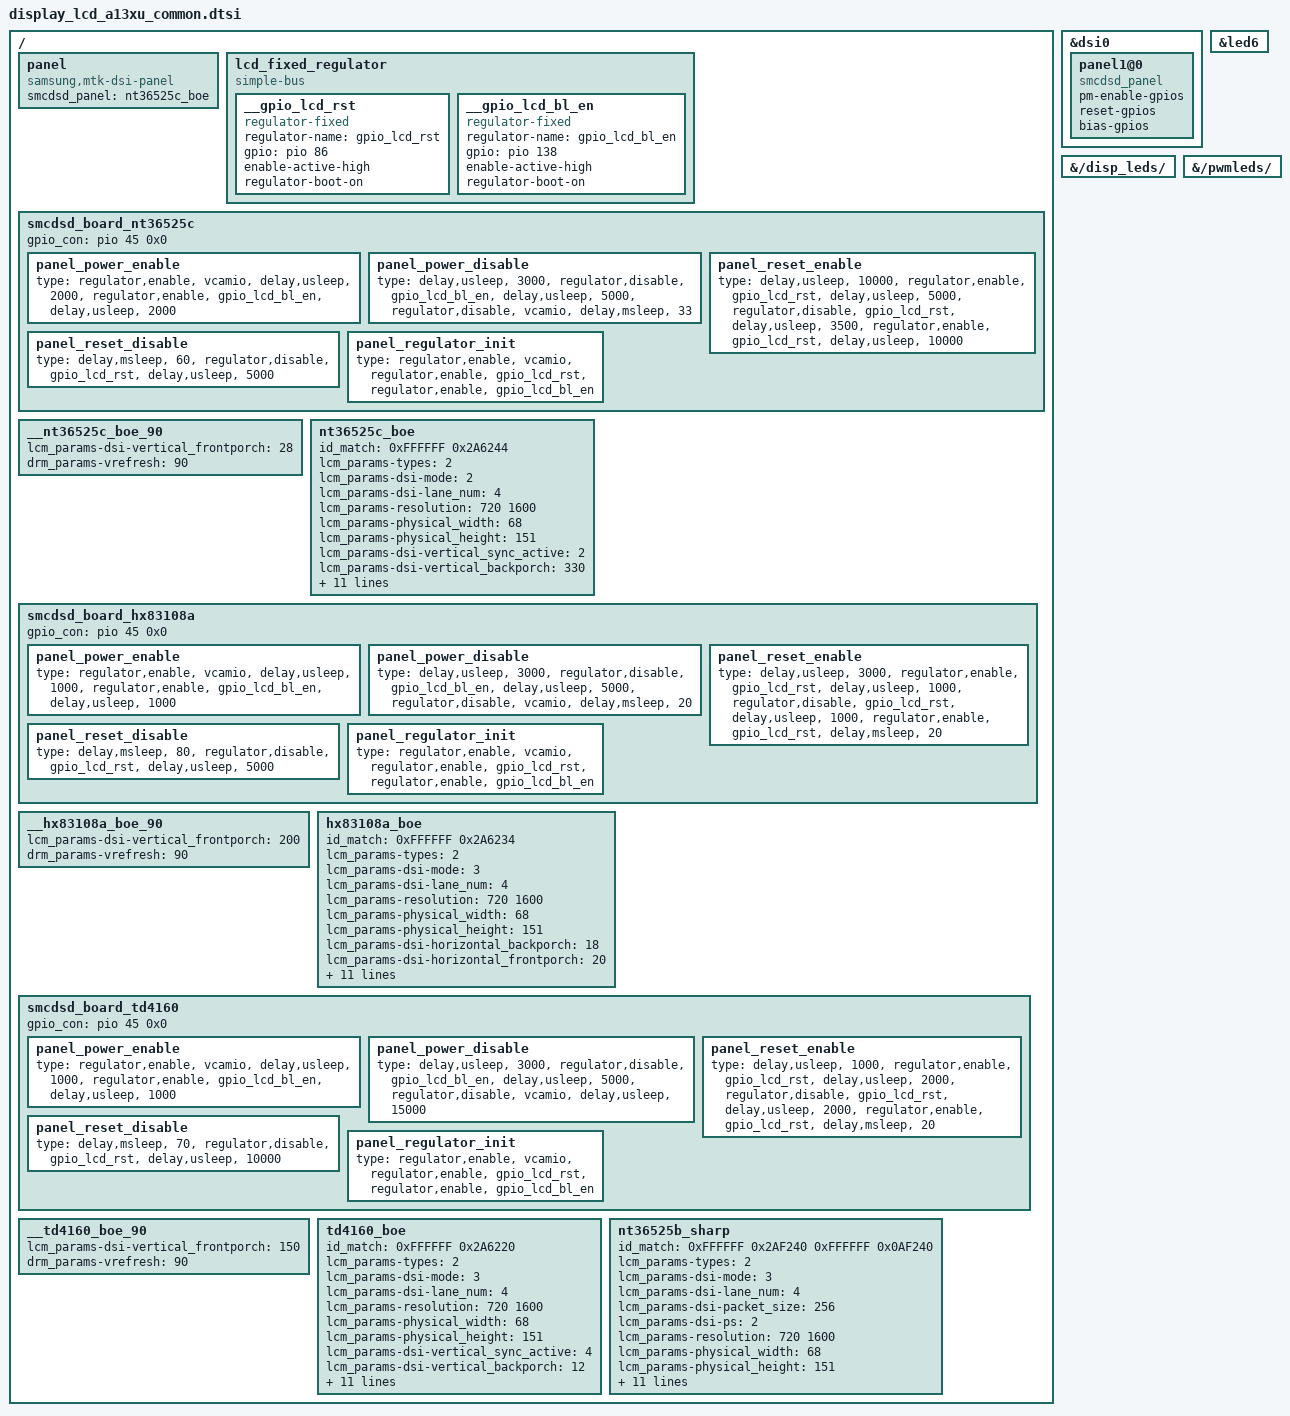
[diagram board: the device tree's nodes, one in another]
/*
 * SAMSUNG LCD Panel Device Tree Source
 *
 * Copyright (c) Samsung Electronics Co., Ltd.
 *		http://www.samsung.com
 *
 * This program is free software; you can redistribute it and/or modify
 * it under the terms of the GNU General Public License version 2 as
 * published by the Free Software Foundation.
 */

/ {
	fragment@led {
		target-path = "/disp_leds/";
		__overlay__ {
			compatible;
		};
	};

	fragment@pwm {
		target-path = "/pwmleds/";
		__overlay__ {
			compatible;
		};
	};

	fragment@lcd {
		target-path = "/";
		__overlay__ {
			panel {
				compatible = "samsung,mtk-dsi-panel";
				smcdsd_panel = <&nt36525c_boe>;
			};

			lcd_fixed_regulator: lcd_fixed_regulator {
				compatible = "simple-bus";

				__gpio_lcd_rst: __gpio_lcd_rst {
					compatible = "regulator-fixed";
					regulator-name = "gpio_lcd_rst";
					gpio = <&pio 86 0>;	/* LCD_RST */
					enable-active-high;
					regulator-boot-on;
				};
				__gpio_lcd_bl_en: __gpio_lcd_bl_en {
					compatible = "regulator-fixed";
					regulator-name = "gpio_lcd_bl_en";
					gpio = <&pio 138 0>;	/* LCD_BL_EN */
					enable-active-high;
					regulator-boot-on;
				};
			};

			smcdsd_board_nt36525c: smcdsd_board_nt36525c {
				gpio_con = <&pio 45 0x0>;	/* LCD_CON_DET */
				//gpio_det = <&pio 6 0x1>;	/* LCD_ESD_DET */

				panel_power_enable {
					type =
					"regulator,enable",	"vcamio",
					"delay,usleep",	"2000",
					"regulator,enable",	"gpio_lcd_bl_en",
					"delay,usleep",	"2000";
				};
				panel_power_disable {
					type =
					"delay,usleep",	"3000",
					"regulator,disable",	"gpio_lcd_bl_en",
					"delay,usleep",	"5000",
					"regulator,disable",	"vcamio",
					"delay,msleep",	"33";
				};
				panel_reset_enable {
					type =
					"delay,usleep",	"10000",
					"regulator,enable",	"gpio_lcd_rst",
					"delay,usleep",	"5000",
					"regulator,disable",	"gpio_lcd_rst",
					"delay,usleep",	"3500",
					"regulator,enable",	"gpio_lcd_rst",
					"delay,usleep",	"10000";
				};
				panel_reset_disable {
					type =
					"delay,msleep",	"60",
					"regulator,disable",	"gpio_lcd_rst",
					"delay,usleep",	"5000";
				};
				panel_regulator_init {
					type =
					"regulator,enable",	"vcamio",
					"regulator,enable",	"gpio_lcd_rst",
					"regulator,enable",	"gpio_lcd_bl_en";
				};
			};

			__nt36525c_boe_90: __nt36525c_boe_90 {
				lcm_params-dsi-vertical_frontporch = <28>;	/* 60Hz: 1009, 90Hz: 28 */

				drm_params-vrefresh = <90>;
			};

			nt36525c_boe: nt36525c_boe {
				/* id_match: MASK(HEX) EXPECT(HEX) */
				id_match = <
					0xFFFFFF 0x2A6244	/* A13X */
				>;
				lcm_params-types = <2>; /* 0: LCM_TYPE_DBI, 1: LCM_TYPE_DPI, 2: LCM_TYPE_DSI */
				lcm_params-dsi-mode = <2>;	/* 0: CMD, 1: SYNC_PULSE_VDO, 2: SYNC_EVENT_VDO, 3: BURST_VDO */
				lcm_params-dsi-lane_num = <4>;

				lcm_params-resolution = <720 1600>;
				lcm_params-physical_width = <68>;		/* 67.93mm x 150.96mm */
				lcm_params-physical_height = <151>;

				lcm_params-dsi-vertical_sync_active = <2>;
				lcm_params-dsi-vertical_backporch = <330>;
				lcm_params-dsi-vertical_frontporch = <1009>;	/* 60Hz: 1009, 90Hz: 28 */
				lcm_params-dsi-horizontal_sync_active = <2>;
				lcm_params-dsi-horizontal_backporch = <34>;
				lcm_params-dsi-horizontal_frontporch = <24>;

				lcm_params-dsi-data_rate = <898>;
				lcm_params-dsi-ssc_disable = <1>;
				lcm_params-dsi-cont_clock = <1>;

				drm_params-vrefresh = <60>;

				ext_params-dyn_fps-vact_timing_fps = <90>;

				vrr_info = <&nt36525c_boe &__nt36525c_boe_90>;

				smcdsd_board = <&smcdsd_board_nt36525c>;
			};

			smcdsd_board_hx83108a: smcdsd_board_hx83108a {
				gpio_con = <&pio 45 0x0>;	/* LCD_CON_DET */
				//gpio_det = <&pio 6 0x1>;	/* LCD_ESD_DET */

				panel_power_enable {
					type =
					"regulator,enable",	"vcamio",
					"delay,usleep",	"1000",
					"regulator,enable",	"gpio_lcd_bl_en",
					"delay,usleep",	"1000";
				};
				panel_power_disable {
					type =
					"delay,usleep",	"3000",
					"regulator,disable",	"gpio_lcd_bl_en",
					"delay,usleep",	"5000",
					"regulator,disable",	"vcamio",
					"delay,msleep",	"20";
				};
				panel_reset_enable {
					type =
					"delay,usleep",	"3000",
					"regulator,enable",	"gpio_lcd_rst",
					"delay,usleep",	"1000",
					"regulator,disable",	"gpio_lcd_rst",
					"delay,usleep",	"1000",
					"regulator,enable",	"gpio_lcd_rst",
					"delay,msleep",	"20";
				};
				panel_reset_disable {
					type =
					"delay,msleep",	"80",
					"regulator,disable",	"gpio_lcd_rst",
					"delay,usleep",	"5000";
				};
				panel_regulator_init {
					type =
					"regulator,enable",	"vcamio",
					"regulator,enable",	"gpio_lcd_rst",
					"regulator,enable",	"gpio_lcd_bl_en";
				};
			};

			__hx83108a_boe_90: __hx83108a_boe_90 {
				lcm_params-dsi-vertical_frontporch = <200>;	/* 60Hz: 1116, 90Hz: 200 */

				drm_params-vrefresh = <90>;
			};

			hx83108a_boe: hx83108a_boe {
				/* id_match: MASK(HEX) EXPECT(HEX) */
				id_match = <
					0xFFFFFF 0x2A6234	/* A13X */
				>;
				lcm_params-types = <2>; /* 0: LCM_TYPE_DBI, 1: LCM_TYPE_DPI, 2: LCM_TYPE_DSI */
				lcm_params-dsi-mode = <3>;	/* 0: CMD, 1: SYNC_PULSE_VDO, 2: SYNC_EVENT_VDO, 3: BURST_VDO */
				lcm_params-dsi-lane_num = <4>;

				lcm_params-resolution = <720 1600>;
				lcm_params-physical_width = <68>;		/* 67.932(H) x 150.96(V) (mm) */
				lcm_params-physical_height = <151>;

				lcm_params-dsi-horizontal_backporch = <18>;
				lcm_params-dsi-horizontal_frontporch = <20>;
				lcm_params-dsi-horizontal_sync_active = <20>;
				lcm_params-dsi-vertical_backporch = <20>;
				lcm_params-dsi-vertical_frontporch = <1116>;	/* 60Hz: 1116, 90Hz: 200 */
				lcm_params-dsi-vertical_sync_active = <8>;

				lcm_params-dsi-data_rate = <834>;
				lcm_params-dsi-ssc_disable = <1>;
				lcm_params-dsi-cont_clock = <1>;

				drm_params-vrefresh = <60>;

				ext_params-dyn_fps-vact_timing_fps = <90>;

				vrr_info = <&hx83108a_boe &__hx83108a_boe_90>;

				smcdsd_board = <&smcdsd_board_hx83108a>;
			};

			smcdsd_board_td4160: smcdsd_board_td4160 {
				gpio_con = <&pio 45 0x0>;	/* LCD_CON_DET */
				//gpio_det = <&pio 6 0x1>;	/* LCD_ESD_DET */

				panel_power_enable {
					type =
					"regulator,enable",	"vcamio",
					"delay,usleep",	"1000",
					"regulator,enable",	"gpio_lcd_bl_en",
					"delay,usleep",	"1000";
				};
				panel_power_disable {
					type =
					"delay,usleep",	"3000",
					"regulator,disable",	"gpio_lcd_bl_en",
					"delay,usleep",	"5000",
					"regulator,disable",	"vcamio",
					"delay,usleep",	"15000";
				};
				panel_reset_enable {
					type =
					"delay,usleep",	"1000",
					"regulator,enable",	"gpio_lcd_rst",
					"delay,usleep",	"2000",
					"regulator,disable",	"gpio_lcd_rst",
					"delay,usleep",	"2000",
					"regulator,enable",	"gpio_lcd_rst",
					"delay,msleep",	"20";
				};
				panel_reset_disable {
					type =
					"delay,msleep",	"70",
					"regulator,disable",	"gpio_lcd_rst",
					"delay,usleep",	"10000";
				};
				panel_regulator_init {
					type =
					"regulator,enable",	"vcamio",
					"regulator,enable",	"gpio_lcd_rst",
					"regulator,enable",	"gpio_lcd_bl_en";
				};
			};

			__td4160_boe_90: __td4160_boe_90 {
				lcm_params-dsi-vertical_frontporch = <150>;	/* 60Hz: 1033, 90Hz: 150 */

				drm_params-vrefresh = <90>;
			};

			td4160_boe: td4160_boe {
				/* id_match: MASK(HEX) EXPECT(HEX) */
				id_match = <
					0xFFFFFF 0x2A6220	/* A13X */
				>;
				lcm_params-types = <2>; /* 0: LCM_TYPE_DBI, 1: LCM_TYPE_DPI, 2: LCM_TYPE_DSI */
				lcm_params-dsi-mode = <3>;	/* 0: CMD, 1: SYNC_PULSE_VDO, 2: SYNC_EVENT_VDO, 3: BURST_VDO */
				lcm_params-dsi-lane_num = <4>;

				lcm_params-resolution = <720 1600>;
				lcm_params-physical_width = <68>;		/* 67.93mm x 150.96mm */
				lcm_params-physical_height = <151>;

				lcm_params-dsi-vertical_sync_active = <4>;
				lcm_params-dsi-vertical_backporch = <12>;
				lcm_params-dsi-vertical_frontporch = <1033>;	/* 60Hz: 1033, 90Hz: 150 */
				lcm_params-dsi-horizontal_sync_active = <2>;
				lcm_params-dsi-horizontal_backporch = <20>;
				lcm_params-dsi-horizontal_frontporch = <64>;

				lcm_params-dsi-data_rate = <834>;
				lcm_params-dsi-ssc_disable = <1>;
				lcm_params-dsi-cont_clock = <1>;

				drm_params-vrefresh = <60>;

				ext_params-dyn_fps-vact_timing_fps = <90>;

				vrr_info = <&td4160_boe &__td4160_boe_90>;

				smcdsd_board = <&smcdsd_board_td4160>;
			};

			nt36525b_sharp: nt36525b_sharp {
				/* id_match: MASK(HEX) EXPECT(HEX) */
				id_match = <
					0xFFFFFF 0x2AF240	/* A32X */
					0xFFFFFF 0x0AF240	/* A12S */
				>;
				lcm_params-types = <2>; /* 0: LCM_TYPE_DBI, 1: LCM_TYPE_DPI, 2: LCM_TYPE_DSI */
				lcm_params-dsi-mode = <3>;	/* 0: CMD, 1: SYNC_PULSE_VDO, 2: SYNC_EVENT_VDO, 3: BURST_VDO */
				lcm_params-dsi-lane_num = <4>;
				lcm_params-dsi-packet_size = <256>;
				lcm_params-dsi-ps = <2>; /* 2: LCM_PACKED_PS_24BIT_RGB888 */

				lcm_params-resolution = <720 1600>;
				lcm_params-physical_width = <68>;		/* 67.932 x 150.96 */
				lcm_params-physical_height = <151>;

				lcm_params-dsi-vertical_sync_active = <2>;
				lcm_params-dsi-vertical_backporch = <254>;
				lcm_params-dsi-vertical_frontporch = <18>;
				lcm_params-dsi-horizontal_sync_active = <30>;
				lcm_params-dsi-horizontal_backporch = <50>;
				lcm_params-dsi-horizontal_frontporch = <90>;

				lcm_params-dsi-data_rate = <639>;
				lcm_params-dsi-ssc_disable = <1>;
				lcm_params-dsi-cont_clock = <1>;

				drm_params-vrefresh = <60>;

				smcdsd_board = <&smcdsd_board_nt36525c>;
			};
		};
	};
};

&dsi0 {
	panel1@0 {
		compatible = "smcdsd_panel";
		pm-enable-gpios;
		reset-gpios;
		bias-gpios;
	};
};

/* dts clean section */
&led6 {
	compatible;
};

